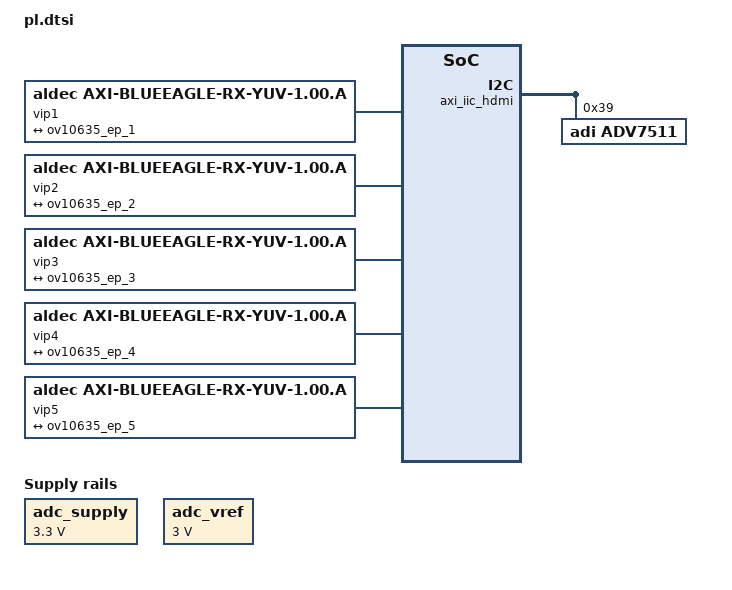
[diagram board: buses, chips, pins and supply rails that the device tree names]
/*
 * CAUTION: This file is automatically generated by Xilinx.
 * Version:  
 * Today is: Mon Aug 21 14:07:54 2017
*/


/ {
	amba_pl: amba_pl {
		#address-cells = <1>;
		#size-cells = <1>;
		compatible = "simple-bus";
		ranges;
		
		axi_gpio_switches: gpio@41210000 {
			#gpio-cells = <2>;
			#interrupt-cells = <2>;
			compatible = "xlnx,xps-gpio-1.00.a";
			gpio-controller ;
			reg = <0x41210000 0x10000>;
			xlnx,all-inputs = <0x1>;
			xlnx,all-inputs-2 = <0x0>;
			xlnx,all-outputs = <0x0>;
			xlnx,all-outputs-2 = <0x0>;
			xlnx,dout-default = <0x00000000>;
			xlnx,dout-default-2 = <0x00000000>;
			xlnx,gpio-width = <0x8>;
			xlnx,gpio2-width = <0x20>;
			xlnx,interrupt-present = <0x1>;
			xlnx,is-dual = <0x0>;
			xlnx,tri-default = <0xFFFFFFFF>;
			xlnx,tri-default-2 = <0xFFFFFFFF>;
		};		
		
		axi_gpio_des: gpio@41230000 {
			#gpio-cells = <2>;
			compatible = "xlnx,xps-gpio-1.00.a";
			gpio-controller ;
			reg = <0x41230000 0x10000>;
			xlnx,all-inputs = <0x0>;
			xlnx,all-inputs-2 = <0x0>;
			xlnx,all-outputs = <0x1>;
			xlnx,all-outputs-2 = <0x0>;
			xlnx,dout-default = <0x0000000E>;
			xlnx,dout-default-2 = <0x00000000>;
			xlnx,gpio-width = <0x4>;
			xlnx,gpio2-width = <0x20>;
			xlnx,interrupt-present = <0x0>;
			xlnx,is-dual = <0x0>;
			xlnx,tri-default = <0xFFFFFFFF>;
			xlnx,tri-default-2 = <0xFFFFFFFF>;
		};
		
		gpio-reset {
			compatible = "linux,gpio-reset";

			multides {
				/* Put PDB line low for a 1 ms during bootup*/
				gpios = <&axi_gpio_des 1 0>;
				asserted-state = <0>;
				duration-ms = <1>;
				auto;
			};
		};
		
		axi_gpio_radar: gpio@41220000 {
			#gpio-cells = <2>;
			compatible = "xlnx,xps-gpio-1.00.a";
			gpio-controller ;
			reg = <0x41220000 0x10000>;
			xlnx,all-inputs = <0x1>;
			xlnx,all-inputs-2 = <0x1>;
			xlnx,all-outputs = <0x0>;
			xlnx,all-outputs-2 = <0x0>;
			xlnx,dout-default = <0x00000000>;
			xlnx,dout-default-2 = <0x00000000>;
			xlnx,gpio-width = <0x1>;
			xlnx,gpio2-width = <0x1>;
			xlnx,interrupt-present = <0x0>;
			xlnx,is-dual = <0x0>;
			xlnx,tri-default = <0xFFFFFFFF>;
			xlnx,tri-default-2 = <0xFFFFFFFF>;
		};
		
		adc_supply: fixedregulator-vcc {
			compatible = "regulator-fixed";
			regulator-name = "fixed-supply";
			regulator-min-microvolt = <3300000>;
			regulator-max-microvolt = <3300000>;
		};

		adc_vref: fixedregulator-refin {
			compatible = "regulator-fixed";
			regulator-name = "fixed-supply";
			regulator-min-microvolt = <3000000>;
			regulator-max-microvolt = <3000000>;
		};
		
		axi_gpio_lidar_mode: gpio@41250000 {
			#gpio-cells = <2>;
			compatible = "xlnx,xps-gpio-1.00.a";
			gpio-controller ;
			reg = <0x41250000 0x10000>;
			xlnx,all-inputs = <0x1>;
			xlnx,all-inputs-2 = <0x0>;
			xlnx,all-outputs = <0x0>;
			xlnx,all-outputs-2 = <0x1>;
			xlnx,dout-default = <0x00000000>;
			xlnx,dout-default-2 = <0x00000000>;
			xlnx,gpio-width = <0x1>;
			xlnx,gpio2-width = <0x1>;
			xlnx,interrupt-present = <0x0>;
			xlnx,is-dual = <0x1>;
			xlnx,tri-default = <0xFFFFFFFF>;
			xlnx,tri-default-2 = <0xFFFFFFFF>;
		};

		axi_gpio_ov_ctrl_0: gpio@41200000 {
			#gpio-cells = <2>;
			#interrupt-cells = <2>;
			compatible = "xlnx,xps-gpio-1.00.a";
			gpio-controller ;
			reg = <0x41200000 0x10000>;
			xlnx,all-inputs = <0x0>;
			xlnx,all-inputs-2 = <0x0>;
			xlnx,all-outputs = <0x1>;
			xlnx,all-outputs-2 = <0x0>;
			xlnx,dout-default = <0x00000155>;
			xlnx,dout-default-2 = <0x00000000>;
			xlnx,gpio-width = <0xA>;
			xlnx,gpio2-width = <0x20>;
			xlnx,interrupt-present = <0x0>;
			xlnx,is-dual = <0x0>;
			xlnx,tri-default = <0xFFFFFFFF>;
			xlnx,tri-default-2 = <0xFFFFFFFF>;
		};
		
		axi_timer_0: timer@42800000 {
			clock-frequency = <100000000>;			
			#pwm-cells = <2>;
			clocks = <&clkc 15>;
			compatible = "xlnx,pwm-xlnx";			
			reg = <0x42800000 0x10000>;
			xlnx,count-width = <0x20>;
			xlnx,gen0-assert = <0x1>;
			xlnx,gen1-assert = <0x1>;
			xlnx,one-timer-only = <0x0>;
			xlnx,trig0-assert = <0x1>;
			xlnx,trig1-assert = <0x1>;
		};
		
		axi_vdma_des1: dma@43010000 {
			#dma-cells = <1>;
			clocks = <&clkc 15>, <&clkc 16>, <&clkc 16>;
			clock-names = "s_axi_lite_aclk", "m_axi_mm2s_aclk", "m_axis_mm2s_aclk";
			compatible = "xlnx,axi-vdma-1.00.a";
			interrupt-parent = <&intc>;
			interrupts = <0 32 4>;
			reg = <0x43010000 0x10000>;
			dma-ranges = <0x00000000 0x00000000 0x40000000>;
			xlnx,addrwidth = <0x20>;
			xlnx,flush-fsync = <0x1>;
			xlnx,num-fstores = <0x1>;
			dma-channel@43010030 {
				compatible = "xlnx,axi-vdma-s2mm-channel";
				interrupts = <0 32 4>;
				xlnx,datawidth = <0x10>;
				xlnx,device-id = <0x1>;
				xlnx,genlock-mode;
			};
		};
		
		axi_vdma_des2: dma@43020000 {
			#dma-cells = <1>;
			clocks = <&clkc 15>, <&clkc 16>, <&clkc 16>;
			clock-names = "s_axi_lite_aclk", "m_axi_s2mm_aclk", "m_axis_s2mm_aclk";
			compatible = "xlnx,axi-vdma-1.00.a";
			interrupt-parent = <&intc>;
			interrupts = <0 33 4>;
			reg = <0x43020000 0x10000>;
			dma-ranges = <0x00000000 0x00000000 0x40000000>;
			xlnx,addrwidth = <0x20>;
			xlnx,flush-fsync = <0x1>;
			xlnx,num-fstores = <0x1>;
			dma-channel@43020030 {
				compatible = "xlnx,axi-vdma-s2mm-channel";
				interrupts = <0 33 4>;
				xlnx,datawidth = <0x10>;
				xlnx,device-id = <0x2>;
				xlnx,genlock-mode;
			};
		};
		
		axi_vdma_des3: dma@43030000 {
			#dma-cells = <1>;
			clocks = <&clkc 15>, <&clkc 16>, <&clkc 16>;
			clock-names = "s_axi_lite_aclk", "m_axi_s2mm_aclk", "m_axis_s2mm_aclk";
			compatible = "xlnx,axi-vdma-1.00.a";
			interrupt-parent = <&intc>;
			interrupts = <0 34 4>;
			reg = <0x43030000 0x10000>;
			dma-ranges = <0x00000000 0x00000000 0x40000000>;
			xlnx,addrwidth = <0x20>;
			xlnx,flush-fsync = <0x1>;
			xlnx,num-fstores = <0x1>;
			dma-channel@43030030 {
				compatible = "xlnx,axi-vdma-s2mm-channel";
				interrupts = <0 34 4>;
				xlnx,datawidth = <0x10>;
				xlnx,device-id = <0x3>;
				xlnx,genlock-mode;
			};
		};
		
		axi_vdma_des4: dma@43040000 {
			#dma-cells = <1>;
			clocks = <&clkc 15>, <&clkc 16>, <&clkc 16>;
			clock-names = "s_axi_lite_aclk", "m_axi_s2mm_aclk", "m_axis_s2mm_aclk";
			compatible = "xlnx,axi-vdma-1.00.a";
			interrupt-parent = <&intc>;
			interrupts = <0 35 4>;
			reg = <0x43040000 0x10000>;
			dma-ranges = <0x00000000 0x00000000 0x40000000>;
			xlnx,addrwidth = <0x20>;
			xlnx,flush-fsync = <0x1>;
			xlnx,num-fstores = <0x1>;
			dma-channel@43040030 {
				compatible = "xlnx,axi-vdma-s2mm-channel";
				interrupts = <0 35 4>;
				xlnx,datawidth = <0x10>;
				xlnx,device-id = <0x4>;
				xlnx,genlock-mode;
			};
		};
		
		axi_vdma_des5: dma@43050000 {
			#dma-cells = <1>;
			clocks = <&clkc 15>, <&clkc 16>, <&clkc 16>;
			clock-names = "s_axi_lite_aclk", "m_axi_s2mm_aclk", "m_axis_s2mm_aclk";
			compatible = "xlnx,axi-vdma-1.00.a";
			interrupt-parent = <&intc>;
			interrupts = <0 36 4>;
			reg = <0x43050000 0x10000>;
			dma-ranges = <0x00000000 0x00000000 0x40000000>;
			xlnx,addrwidth = <0x20>;
			xlnx,flush-fsync = <0x1>;
			xlnx,num-fstores = <0x1>;
			dma-channel@43050030 {
				compatible = "xlnx,axi-vdma-s2mm-channel";
				interrupts = <0 36 4>;
				xlnx,datawidth = <0x10>;
				xlnx,device-id = <0x5>;
				xlnx,genlock-mode;
			};
		};
		
		vip1 {
			compatible = "aldec,axi-blueeagle-rx-yuv-1.00.a";

			dmas = <&axi_vdma_des1 0>;
			dma-names = "video";

			port {
				vip_ep_1: endpoint {
					remote-endpoint = <&ov10635_ep_1>;
				};
			};
		};
		
		vip2 {
			compatible = "aldec,axi-blueeagle-rx-yuv-1.00.a";

			dmas = <&axi_vdma_des2 0>;
			dma-names = "video";

			port {
				vip_ep_2: endpoint {
					remote-endpoint = <&ov10635_ep_2>;					
				};
			};
		};
		
		vip3 {
			compatible = "aldec,axi-blueeagle-rx-yuv-1.00.a";

			dmas = <&axi_vdma_des3 0>;
			dma-names = "video";

			port {
				vip_ep_3: endpoint {
					remote-endpoint = <&ov10635_ep_3>;					
				};
			};
		};
		
		vip4 {
			compatible = "aldec,axi-blueeagle-rx-yuv-1.00.a";

			dmas = <&axi_vdma_des4 0>;
			dma-names = "video";

			port {
				vip_ep_4: endpoint {
					remote-endpoint = <&ov10635_ep_4>;					
				};
			};
		};
		
		vip5 {
			compatible = "aldec,axi-blueeagle-rx-yuv-1.00.a";

			dmas = <&axi_vdma_des5 0>;
			dma-names = "video";

			port {
				vip_ep_5: endpoint {
					remote-endpoint = <&ov10635_ep_5>;					
				};
			};
		};
		
		sys_clk_in: sys_clk_in {
			compatible = "fixed-clock";
			#clock-cells = <0>;
			clock-frequency = <200000000>;
			clock-output-names = "sys_clk_in";
		};
		
		adi_axi_clkgen: adi_axi_clkgen@60000000 {
			compatible = "adi,axi-clkgen-2.00.a";
			reg = <0x60000000 0x10000>;
			#clock-cells = <0>;
			xlnx,s-axi-min-size = <0x0000FFFF>;
			clock-output-names = "axi_clkgen";
			clocks = <&sys_clk_in>;
		};
		
		axi_iic_hdmi: i2c@41600000 {
			#address-cells = <1>;
			#size-cells = <0>;
			clock-names = "ref_clk";
			clocks = <&clkc 15>;
			compatible = "xlnx,xps-iic-2.00.a";
			interrupt-parent = <&intc>;
			interrupts = <0 29 4>;
			reg = <0x41600000 0x10000>;
			
			adv7511: adv7511@39 {
				compatible = "adi,adv7511";
				reg = <0x39>;
				adi,input-depth = <8>;
				adi,input-colorspace = "yuv422";
				adi,input-clock = "1x";
				adi,input-style = <2>;
				adi,input-justification = "evenly";
			};
		};
		
		axi_vdma_hdmi: xilinx-vdma@43000000 {
			compatible = "xlnx,axi-vdma-1.00.a";
			#dma-cells = <1>;
			reg = <0x43000000 0x10000>;
			dma-ranges = <0x00000000 0x00000000 0x40000000>;
			xlnx,num-fstores = <0x1>;
			xlnx,flush-fsync = <0x1>;
			xlnx,addrwidth = <0x20>;
			clocks = <&clkc 15>, <&clkc 16>, <&clkc 16>;
			clock-names = "s_axi_lite_aclk", "m_axi_mm2s_aclk", "m_axis_mm2s_aclk";
			interrupt-parent = <&intc>;
			interrupts = <0 30 4>;			
			dma-channel@43000000 {
				compatible = "xlnx,axi-vdma-mm2s-channel";
				interrupts = <0 30 4>;
				xlnx,datawidth = <0x20>;
				xlnx,device-id = <0x0>;
				xlnx,genlock-mode;
			};
		};
		
		v_cresample_0: v_cresample@43c10000 {
			compatible = "xlnx,v-cresample-3.01.a";
			reg = <0x43c10000 0x10000>;
			xlnx,input-format = "yuv444";
			xlnx,output-format = "yuv422";
		};
		
		v_osd_0: v_osd@43c20000 {
			compatible = "xlnx,v-osd-5.01.a";
			reg = <0x43c20000 0x10000>;
			xlnx,num-layers = <1>;
			xlnx,screen-width = <1920>;
		};
		
		v_rgb2ycrcb_0: v_rgb2ycrcb@43c00000 {
			compatible = "xlnx,v-rgb2ycrcb-6.01.a";
			reg = <0x43c00000 0x10000>;
		};
		
		v_tc_0: v_tc@43c30000 {
			compatible = "xlnx,v-tc-5.01.a";
			interrupt-parent = <&intc>;
			interrupts = <0 31 4>;
			reg = <0x43c30000 0x10000>;
		};
		
		xilinx_drm {
			compatible = "xlnx,drm";
			xlnx,osd = <&v_osd_0>;
			xlnx,vtc = <&v_tc_0>;
			xlnx,encoder-slave = <&adv7511>;
			xlnx,connector-type = "HDMIA";
			clocks = <&adi_axi_clkgen>;
			planes {
				xlnx,pixel-format = "yuv422";
				plane0 {
					dmas = <&axi_vdma_hdmi 0>;
					dma-names = "dma";
					xlnx,rgb2yuv = <&v_rgb2ycrcb_0>;
					xlnx,cresample = <&v_cresample_0>;
				};
			};
		};
	};
};
